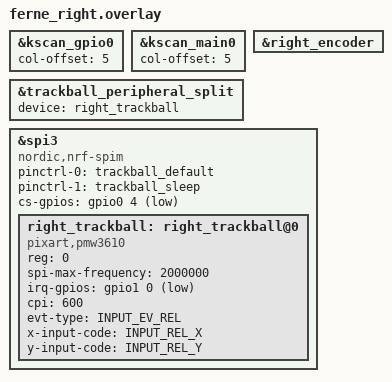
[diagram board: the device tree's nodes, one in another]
/*
 * Copyright (c) 2025 The ZMK Contributors
 *
 * SPDX-License-Identifier: MIT
 */

#include "ferne.dtsi"

&kscan_gpio0 {
	col-offset = <5>;
};

&kscan_main0 {
	col-offset = <5>;
};

&right_encoder {
    status = "okay";
};

&trackball_peripheral_split {
    device = <&right_trackball>;
};

&spi3 {
	status = "okay";
	compatible = "nordic,nrf-spim";
	pinctrl-0 = <&trackball_default>;
	pinctrl-1 = <&trackball_sleep>;
	pinctrl-names = "default", "sleep";
	cs-gpios = <&gpio0 4 GPIO_ACTIVE_LOW>;  //"sel2"

	right_trackball: right_trackball@0 {
		status = "okay";
		compatible = "pixart,pmw3610";
		reg = <0>;
		spi-max-frequency = <2000000>;
		irq-gpios = <&gpio1 0 (GPIO_ACTIVE_LOW | GPIO_PULL_UP)>;
		cpi = <600>;
		evt-type = <INPUT_EV_REL>;
		x-input-code = <INPUT_REL_X>;
		y-input-code = <INPUT_REL_Y>;
	};
};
